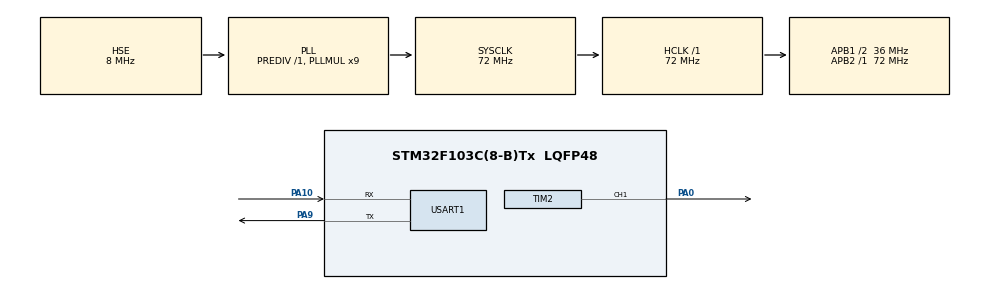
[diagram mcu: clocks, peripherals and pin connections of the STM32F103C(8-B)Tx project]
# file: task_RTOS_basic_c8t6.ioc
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Dma.Request0=USART1_RX
Dma.Request1=USART1_TX
Dma.USART1_RX.0.Direction=DMA_PERIPH_TO_MEMORY
Dma.USART1_RX.0.Instance=DMA1_Channel5
Dma.USART1_RX.0.MemDataAlignment=DMA_MDATAALIGN_BYTE
Dma.USART1_RX.0.MemInc=DMA_MINC_ENABLE
Dma.USART1_RX.0.Mode=DMA_NORMAL
Dma.USART1_RX.0.PeriphDataAlignment=DMA_PDATAALIGN_BYTE
Dma.USART1_RX.0.PeriphInc=DMA_PINC_DISABLE
Dma.USART1_RX.0.Priority=DMA_PRIORITY_LOW
Dma.USART1_TX.1.Direction=DMA_MEMORY_TO_PERIPH
Dma.USART1_TX.1.Instance=DMA1_Channel4
Dma.USART1_TX.1.MemDataAlignment=DMA_MDATAALIGN_BYTE
Dma.USART1_TX.1.MemInc=DMA_MINC_ENABLE
Dma.USART1_TX.1.Mode=DMA_NORMAL
Dma.USART1_TX.1.PeriphDataAlignment=DMA_PDATAALIGN_BYTE
Dma.USART1_TX.1.PeriphInc=DMA_PINC_DISABLE
Dma.USART1_TX.1.Priority=DMA_PRIORITY_LOW
FREERTOS.BinarySemaphores01=BinarySem_Rec,Dynamic,NULL
FREERTOS.Mutexes01=Mutex_UART_Lock,Dynamic,NULL
FREERTOS.Tasks01=myTask_LED,9,128,StartLED_Task,Default,NULL,Dynamic,NULL,NULL;myTask_UART,10,128,StartTask_UART,Default,NULL,Dynamic,NULL,NULL
Mcu.Family=STM32F1
Mcu.Name=STM32F103C(8-B)Tx
Mcu.Package=LQFP48
NVIC.DMA1_Channel4_IRQn=true\:5\:0\:false\:false\:true\:true\:false\:true
NVIC.DMA1_Channel5_IRQn=true\:5\:0\:false\:false\:true\:true\:false\:true
NVIC.PriorityGroup=NVIC_PRIORITYGROUP_4
NVIC.TIM4_IRQn=true\:15\:0\:false\:false\:true\:false\:false\:true
NVIC.TimeBase=TIM4_IRQn
NVIC.TimeBaseIP=TIM4
NVIC.USART1_IRQn=true\:5\:0\:false\:false\:true\:true\:true\:true
PA0-WKUP.Signal=S_TIM2_CH1_ETR
PA10.Mode=Asynchronous
PA10.Signal=USART1_RX
PA13.Mode=Serial_Wire
PA13.Signal=SYS_JTMS-SWDIO
PA14.Mode=Serial_Wire
PA14.Signal=SYS_JTCK-SWCLK
PA9.Mode=Asynchronous
PA9.Signal=USART1_TX
PC14-OSC32_IN.Mode=LSE-External-Oscillator
PC14-OSC32_IN.Signal=RCC_OSC32_IN
PC15-OSC32_OUT.Mode=LSE-External-Oscillator
PC15-OSC32_OUT.Signal=RCC_OSC32_OUT
PD0-OSC_IN.Mode=HSE-External-Oscillator
PD0-OSC_IN.Signal=RCC_OSC_IN
PD1-OSC_OUT.Mode=HSE-External-Oscillator
PD1-OSC_OUT.Signal=RCC_OSC_OUT
ProjectManager.HeapSize=0x200
ProjectManager.StackSize=0x400
ProjectManager.TargetToolchain=MDK-ARM V5.32
RCC.AHBFreq_Value=72000000
RCC.APB1CLKDivider=RCC_HCLK_DIV2
RCC.APB1Freq_Value=36000000
RCC.APB1TimFreq_Value=72000000
RCC.APB2Freq_Value=72000000
RCC.APB2TimFreq_Value=72000000
RCC.HCLKFreq_Value=72000000
RCC.PLLMUL=RCC_PLL_MUL9
RCC.PLLSourceVirtual=RCC_PLLSOURCE_HSE
RCC.SYSCLKFreq_VALUE=72000000
RCC.SYSCLKSource=RCC_SYSCLKSOURCE_PLLCLK
RCC.USBFreq_Value=72000000
SH.S_TIM2_CH1_ETR.0=TIM2_CH1,PWM Generation1 CH1
TIM2.Channel-PWM\ Generation1\ CH1=TIM_CHANNEL_1
TIM2.Period=100-1
TIM2.Prescaler=720-1
USART1.VirtualMode=VM_ASYNC
VP_FREERTOS_VS_CMSIS_V2.Mode=CMSIS_V2
VP_SYS_VS_tim4.Mode=TIM4
board=custom

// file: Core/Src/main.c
/* USER CODE BEGIN Header */
/**
  ******************************************************************************
  * @file           : main.c
  * @brief          : Main program body
  ******************************************************************************
  * @attention
  *
  * <h2><center>&copy; Copyright (c) 2024 STMicroelectronics.
  * All rights reserved.</center></h2>
  *
  * This software component is licensed by ST under Ultimate Liberty license
  * SLA0044, the "License"; You may not use this file except in compliance with
  * the License. You may obtain a copy of the License at:
  *                             www.st.com/SLA0044
  *
  ******************************************************************************
  */
/* USER CODE END Header */
#include "main.h"
#include "cmsis_os.h"
#include "dma.h"
#include "tim.h"
#include "usart.h"
#include "gpio.h"

/* USER CODE BEGIN PV */
 xUSATR_TypeDef xUSART1={0}; //管理串口接收

/* USER CODE END PV */

void SystemClock_Config(void);
void MX_FREERTOS_Init(void);

int main(void)
{

  /* MCU Configuration--------------------------------------------------------*/

  /* Reset of all peripherals, Initializes the Flash interface and the Systick. */
  HAL_Init();

  /* Configure the system clock */
  SystemClock_Config();

  /* Initialize all configured peripherals */
  MX_GPIO_Init();
  MX_DMA_Init();
  MX_TIM2_Init();
  MX_USART1_UART_Init();
  /* USER CODE BEGIN 2 */

  HAL_TIM_Base_Start(&htim2);    //开启时基，cubeMX初始化并不会开启定时器，需要我们手动打开使能定时器
	HAL_TIM_PWM_Start(&htim2,TIM_CHANNEL_1);//开启定时器2的PWM通道1的输出

	HAL_UARTEx_ReceiveToIdle_DMA(&huart1, xUSART1.BuffTemp, sizeof(xUSART1.BuffTemp));    //开启DMA接收完成中断，串口空闲中断
  /* USER CODE END 2 */

  /* Init scheduler */
  osKernelInitialize();  /* Call init function for freertos objects (in freertos.c) */
  MX_FREERTOS_Init();
  /* Start scheduler */
  osKernelStart();

  /* We should never get here as control is now taken by the scheduler */
  /* Infinite loop */
  while (1)
  {

  }
}

void SystemClock_Config(void)
{
  RCC_OscInitTypeDef RCC_OscInitStruct = {0};
  RCC_ClkInitTypeDef RCC_ClkInitStruct = {0};

  /** Initializes the RCC Oscillators according to the specified parameters
  * in the RCC_OscInitTypeDef structure.
  */
  RCC_OscInitStruct.OscillatorType = RCC_OSCILLATORTYPE_HSE;
  RCC_OscInitStruct.HSEState = RCC_HSE_ON;
  RCC_OscInitStruct.HSEPredivValue = RCC_HSE_PREDIV_DIV1;
  RCC_OscInitStruct.HSIState = RCC_HSI_ON;
  RCC_OscInitStruct.PLL.PLLState = RCC_PLL_ON;
  RCC_OscInitStruct.PLL.PLLSource = RCC_PLLSOURCE_HSE;
  RCC_OscInitStruct.PLL.PLLMUL = RCC_PLL_MUL9;
  if (HAL_RCC_OscConfig(&RCC_OscInitStruct) != HAL_OK)
  {
    Error_Handler();
  }
  /** Initializes the CPU, AHB and APB buses clocks
  */
  RCC_ClkInitStruct.ClockType = RCC_CLOCKTYPE_HCLK|RCC_CLOCKTYPE_SYSCLK
                              |RCC_CLOCKTYPE_PCLK1|RCC_CLOCKTYPE_PCLK2;
  RCC_ClkInitStruct.SYSCLKSource = RCC_SYSCLKSOURCE_PLLCLK;
  RCC_ClkInitStruct.AHBCLKDivider = RCC_SYSCLK_DIV1;
  RCC_ClkInitStruct.APB1CLKDivider = RCC_HCLK_DIV2;
  RCC_ClkInitStruct.APB2CLKDivider = RCC_HCLK_DIV1;

  if (HAL_RCC_ClockConfig(&RCC_ClkInitStruct, FLASH_LATENCY_2) != HAL_OK)
  {
    Error_Handler();
  }
}

void HAL_TIM_PeriodElapsedCallback(TIM_HandleTypeDef *htim)
{
  if (htim->Instance == TIM4) {
    HAL_IncTick();
  }
}

void Error_Handler(void)
{
  __disable_irq();
  while (1)
  {
  }
}

/************************ (C) COPYRIGHT STMicroelectronics *****END OF FILE****/

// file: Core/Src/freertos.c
/* USER CODE BEGIN Header */
/**
  ******************************************************************************
  * File Name          : freertos.c
  * Description        : Code for freertos applications
  ******************************************************************************
  * @attention
  *
  * <h2><center>&copy; Copyright (c) 2024 STMicroelectronics.
  * All rights reserved.</center></h2>
  *
  * This software component is licensed by ST under Ultimate Liberty license
  * SLA0044, the "License"; You may not use this file except in compliance with
  * the License. You may obtain a copy of the License at:
  *                             www.st.com/SLA0044
  *
  ******************************************************************************
  */
/* USER CODE END Header */

#include "FreeRTOS.h"
#include "task.h"
#include "main.h"
#include "cmsis_os.h"

/* USER CODE BEGIN Includes */
#include "tim.h"
#include "queue.h"
#include "semphr.h"
/* USER CODE END Includes */

/* Definitions for myTask_LED */
osThreadId_t myTask_LEDHandle;
const osThreadAttr_t myTask_LED_attributes = {
  .name = "myTask_LED",
  .stack_size = 128 * 4,
  .priority = (osPriority_t) osPriorityLow1,
};
/* Definitions for myTask_UART */
osThreadId_t myTask_UARTHandle;
const osThreadAttr_t myTask_UART_attributes = {
  .name = "myTask_UART",
  .stack_size = 128 * 4,
  .priority = (osPriority_t) osPriorityLow2,
};
/* Definitions for Mutex_UART_Lock */
osMutexId_t Mutex_UART_LockHandle;
const osMutexAttr_t Mutex_UART_Lock_attributes = {
  .name = "Mutex_UART_Lock"
};
/* Definitions for BinarySem_Rec */
osSemaphoreId_t BinarySem_RecHandle;
const osSemaphoreAttr_t BinarySem_Rec_attributes = {
  .name = "BinarySem_Rec"
};

/* USER CODE BEGIN FunctionPrototypes */
void breathing_light(float frequency, uint8_t max_brightness);//呼吸灯
/* USER CODE END FunctionPrototypes */

void StartLED_Task(void *argument);
void StartTask_UART(void *argument);

void MX_FREERTOS_Init(void); /* (MISRA C 2004 rule 8.1) */

void MX_FREERTOS_Init(void) {
  /* Create the mutex(es) */
  /* creation of Mutex_UART_Lock */
  Mutex_UART_LockHandle = osMutexNew(&Mutex_UART_Lock_attributes);

  /* Create the semaphores(s) */
  /* creation of BinarySem_Rec */
  BinarySem_RecHandle = osSemaphoreNew(1, 1, &BinarySem_Rec_attributes);

  /* Create the thread(s) */
  /* creation of myTask_LED */
  myTask_LEDHandle = osThreadNew(StartLED_Task, NULL, &myTask_LED_attributes);

  /* creation of myTask_UART */
  myTask_UARTHandle = osThreadNew(StartTask_UART, NULL, &myTask_UART_attributes);

}

void StartLED_Task(void *argument)
{
  /* USER CODE BEGIN StartLED_Task */
	float frequency=0.5;
  uint8_t  max_brightness=100;

  /* Infinite loop */
  for(;;)
  {

		  breathing_light(frequency,max_brightness);

  }
  /* USER CODE END StartLED_Task */
}

void StartTask_UART(void *argument)
{
  /* USER CODE BEGIN StartTask_UART */
  /* Infinite loop */
  for(;;)
  {
		xSemaphoreTake(BinarySem_RecHandle,portMAX_DELAY);//获取信号量

		xSemaphoreTake(Mutex_UART_LockHandle,portMAX_DELAY);//获取互斥锁
		printf("收到: %s\n",xUSART1.ReceiveData);
		xSemaphoreGive(Mutex_UART_LockHandle);//释放互斥锁

  }
  /* USER CODE END StartTask_UART */
}

/* USER CODE BEGIN Application */

/*
*@brief  LED呼吸灯，可通过入口参数调整最大亮度和频率
*@param1 frequency 呼吸灯频率 0.1~2之间比较合适
*@param2 max_brightness 呼吸灯最大亮度  取值0~100
*/
void breathing_light(float frequency, uint8_t max_brightness)
{

	  float T =1000.0/frequency;//单位ms

    // 计算每个阶段的延迟（单位：毫秒）
    uint32_t delay_time_ms = T/(2*max_brightness);

    // 逐渐增加亮度
    for (uint8_t brightness = 0; brightness <= max_brightness; brightness++)
	  {
        SetPWMDuty(&htim2,TIM_CHANNEL_1,brightness);

        vTaskDelay(pdMS_TO_TICKS(delay_time_ms));
    }

    // 逐渐减少亮度
    for (uint8_t brightness = max_brightness; brightness > 0; brightness--)
		{
        SetPWMDuty(&htim2,TIM_CHANNEL_1,brightness);

        vTaskDelay(pdMS_TO_TICKS(delay_time_ms));
    }
}
/* USER CODE END Application */

/************************ (C) COPYRIGHT STMicroelectronics *****END OF FILE****/
